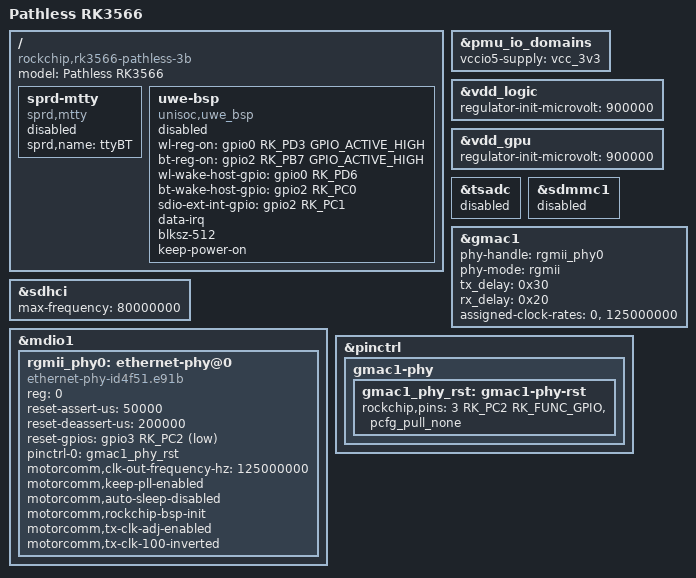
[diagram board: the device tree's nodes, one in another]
// SPDX-License-Identifier: (GPL-2.0+ OR MIT)
/*
 * Pathless RK3566 — mainline DT (hardware ref: Orange Pi 3B V1.x)
 * Includes upstream rk3566-orangepi-3b.dtsi; brand + UWE5622 WiFi/BT nodes are Pathless-owned.
 * WiFi/BT GPIO layout matches Armbian board-orangepi3b-add-uwe5622-wifi-bt-nodes.patch.
 */

/dts-v1/;

#include "rk3566-orangepi-3b.dtsi"

/ {
	model = "Pathless RK3566";
	compatible = "rockchip,rk3566-pathless-3b", "rockchip,rk3566";

	sprd-mtty {
		compatible = "sprd,mtty";
		sprd,name = "ttyBT";
		/* sprdbt_tty oopses in get_loopcheck_status unless marlin/uwe-bsp is up. */
		status = "disabled";
	};

	uwe-bsp {
		compatible = "unisoc,uwe_bsp";
		wl-reg-on = <&gpio0 RK_PD3 GPIO_ACTIVE_HIGH>;
		bt-reg-on = <&gpio2 RK_PB7 GPIO_ACTIVE_HIGH>;
		wl-wake-host-gpio = <&gpio0 RK_PD6 GPIO_ACTIVE_HIGH>;
		bt-wake-host-gpio = <&gpio2 RK_PC0 GPIO_ACTIVE_HIGH>;
		sdio-ext-int-gpio = <&gpio2 RK_PC1 GPIO_ACTIVE_HIGH>;
		data-irq;
		blksz-512;
		keep-power-on;
		status = "disabled";
	};
};

&pmu_io_domains {
	vccio5-supply = <&vcc_3v3>;
};

/* Match vendor: RK809 DCDC must have an explicit 900 mV boot voltage. */
&vdd_logic {
	regulator-init-microvolt = <900000>;
};

&vdd_gpu {
	regulator-init-microvolt = <900000>;
};

/*
 * Vendor tsadc needs OTP nvmem trim (trim_base / cpu-tsadc-trim-*).
 * Mainline rk356x-base.dtsi has none; enabling TSHUT CRU-resets the SoC.
 */
&tsadc {
	status = "disabled";
};

&sdmmc1 {
	status = "disabled";
};

&gmac1 {
	phy-handle = <&rgmii_phy0>;
	phy-mode = "rgmii";
	tx_delay = <0x30>;
	rx_delay = <0x20>;
	assigned-clock-rates = <0>, <125000000>;
	status = "okay";
};

&sdhci {
	max-frequency = <80000000>;
	/delete-property/ mmc-hs200-1_8v;
	/delete-property/ mmc-hs400-1_8v;
	/delete-property/ mmc-hs400-enhanced-strobe;
};

/*
 * Hardware is YT8531 at MDIO 0, reset GPIO3_PC2, VCCIO5 3.3V.
 * 100M needs PHY TXC invert; MAC tx_delay=0x30 rx_delay=0x20
 * (best of 0x10/0x20/0x30 on board). Vendor analog init: CLKOUT 0xd0,
 * RXC duty, 100M BGS.
 */
&mdio1 {
	rgmii_phy0: ethernet-phy@0 {
		compatible = "ethernet-phy-id4f51.e91b",
			     "ethernet-phy-ieee802.3-c22";
		reg = <0>;
		reset-assert-us = <50000>;
		reset-deassert-us = <200000>;
		reset-gpios = <&gpio3 RK_PC2 GPIO_ACTIVE_LOW>;
		pinctrl-names = "default";
		pinctrl-0 = <&gmac1_phy_rst>;
		motorcomm,clk-out-frequency-hz = <125000000>;
		motorcomm,keep-pll-enabled;
		motorcomm,auto-sleep-disabled;
		motorcomm,rockchip-bsp-init;
		motorcomm,tx-clk-adj-enabled;
		motorcomm,tx-clk-100-inverted;
	};
};

&pinctrl {
	gmac1-phy {
		gmac1_phy_rst: gmac1-phy-rst {
			rockchip,pins = <3 RK_PC2 RK_FUNC_GPIO &pcfg_pull_none>;
		};
	};
};
